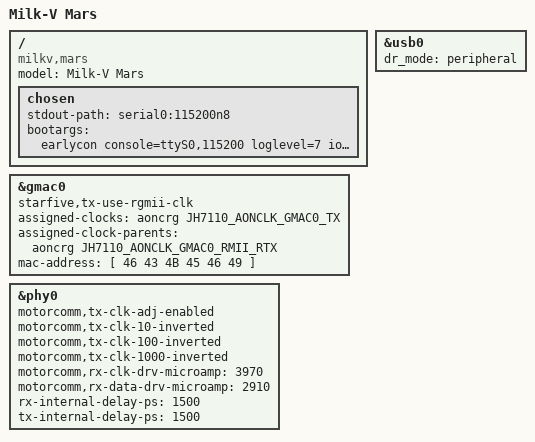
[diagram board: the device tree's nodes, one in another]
// SPDX-License-Identifier: GPL-2.0 OR MIT
/*
 * Copyright (C) 2023 Jisheng Zhang <jszhang@kernel.org>
 */

/dts-v1/;
#include "jh7110-common.dtsi"

/ {
	model = "Milk-V Mars";
	compatible = "milkv,mars", "starfive,jh7110";

	chosen {
		stdout-path = "serial0:115200n8";
		bootargs = "earlycon console=ttyS0,115200 loglevel=7 iomem=relaxed";
	};
};

&gmac0 {
	starfive,tx-use-rgmii-clk;
	assigned-clocks = <&aoncrg JH7110_AONCLK_GMAC0_TX>;
	assigned-clock-parents = <&aoncrg JH7110_AONCLK_GMAC0_RMII_RTX>;
	mac-address = [ 46 43 4B 45 46 49 ];
};


&phy0 {
	motorcomm,tx-clk-adj-enabled;
	motorcomm,tx-clk-10-inverted;
	motorcomm,tx-clk-100-inverted;
	motorcomm,tx-clk-1000-inverted;
	motorcomm,rx-clk-drv-microamp = <3970>;
	motorcomm,rx-data-drv-microamp = <2910>;
	rx-internal-delay-ps = <1500>;
	tx-internal-delay-ps = <1500>;
};

&usb0 {
	status = "okay";
	// dr_mode = "otg";
	dr_mode = "peripheral";
};
